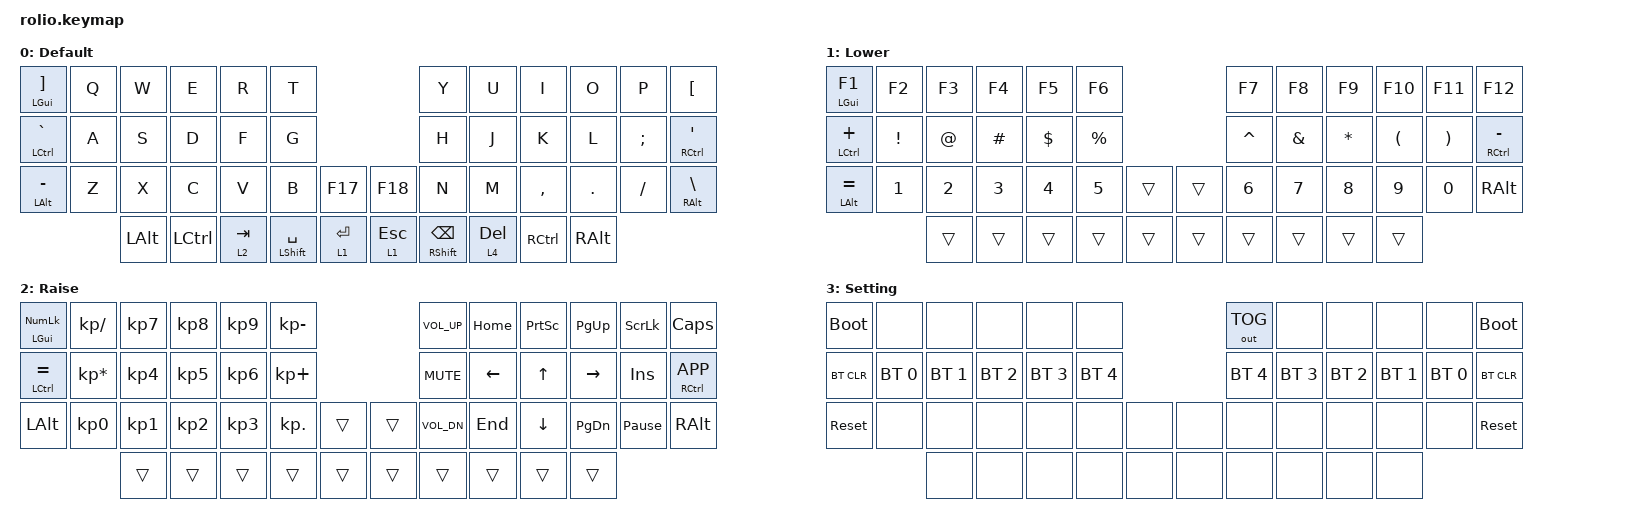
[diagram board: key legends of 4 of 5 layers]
/*
 * Copyright (c) 2023 The ZMK Contributors
 *
 * SPDX-License-Identifier: MIT
 */

#include <behaviors.dtsi>
#include <dt-bindings/zmk/keys.h>
#include <dt-bindings/zmk/bt.h>
#include <dt-bindings/zmk/outputs.h>
#include <dt-bindings/zmk/backlight.h>
#include "elpekenin/behaviors.dtsi"

#define ZMK_POINTING_DEFAULT_SCRL_VAL 100
#include <dt-bindings/zmk/pointing.h>

// Helpful macros borrowed from AndrewMSHowe
#define ___ &trans

// Layer numbers for use by the keymap & macros
#define Default 0
#define Lower 1
#define Raise 2
#define Setting 3
#define Navi 4

/ {
    conditional_layers {
        compatible = "zmk,conditional-layers";

        tri-layer {
            if-layers = <1 2>;
            then-layer = <3>;
        };

        tri-layer1 {
            if-layers = <4 1>;
            then-layer = <3>;
        };
    };


    keymap {
        compatible = "zmk,keymap";

        default_layer {
            display-name = "Default";
            sensor-bindings = <&inc_dec_kp UP DOWN &inc_dec_kp LEFT RIGHT>;
            bindings = <
&mt LGUI RBKT		&kp Q		&kp W			&kp E			&kp R			&kp T												&kp Y				&kp U			&kp I			&kp O		&kp P		&kp LBKT
&mt LCTRL GRAVE		&kp A		&kp S			&kp D			&kp F			&kp G												&kp H				&kp J			&kp K			&kp L		&kp SEMI	&mt RCTRL SQT
&mt LALT MINUS		&kp Z		&kp X			&kp C			&kp V			&kp B				&kp F17 		&kp	F18			&kp N				&kp M			&kp COMMA		&kp DOT		&kp FSLH	&mt RALT BSLH
								&kp LALT		&kp LCTRL		&lt 2 TAB		&mt LSHFT SPACE		&lt 1 RET		&lt 1 ESC		&mt RSHFT BSPC		&lt 4 DEL		&kp RCTRL		&kp RALT
            >;
        };

        Lower_layer {
            display-name = "Lower";
            sensor-bindings = <&inc_dec_kp UP DOWN &inc_dec_kp LEFT RIGHT>;
            bindings = <
&mt LGUI F1		&kp F2		&kp F3		&kp F4		&kp F5		&kp F6										&kp F7		&kp F8		&kp F9		&kp F10		&kp F11		&kp F12
&mt LCTRL PLUS	&kp EXCL	&kp AT		&kp HASH	&kp DLLR	&kp PRCNT									&kp CARET	&kp AMPS	&kp STAR	&kp LPAR	&kp RPAR	&mt RCTRL MINUS
&mt LALT EQUAL	&kp N1		&kp N2		&kp N3		&kp N4		&kp N5		&trans				&trans		&kp N6		&kp N7		&kp N8		&kp N9		&kp N0		&kp RALT
							&trans		&trans		&trans		&trans		&trans				&trans		&trans		&trans		&trans		&trans
            >;
        };

        raise_layer {
            display-name = "Raise";
            sensor-bindings = <&inc_dec_kp UP DOWN &inc_dec_kp LEFT RIGHT>;
            bindings = <
&mt LGUI KP_NUM		&kp KP_SLASH		&kp KP_N7	&kp KP_N8	&kp KP_N9	&kp KP_MINUS							&kp C_VOL_UP	&kp HOME	&kp PSCRN	&kp PG_UP	&kp SLCK			&kp CLCK
&mt LCTRL EQUAL		&kp KP_MULTIPLY		&kp KP_N4	&kp KP_N5	&kp KP_N6	&kp KP_PLUS								&kp C_MUTE		&kp LEFT	&kp UP		&kp RIGHT	&kp INS				&mt RCTRL K_APP
&kp LALT			&kp KP_N0			&kp KP_N1	&kp KP_N2	&kp KP_N3	&kp KP_DOT		&trans		&trans		&kp C_VOL_DN	&kp END		&kp DOWN	&kp PG_DN	&kp PAUSE_BREAK		&kp RALT
										&trans		&trans		&trans		&trans			&trans		&trans		&trans			&trans		&trans		&trans
            >;
        };

        Setting_layer {
            display-name = "Setting";
            sensor-bindings = <&inc_dec_kp UP DOWN &inc_dec_kp LEFT RIGHT>;
            bindings = <
&bootloader		&none			&none			&none			&none			&none										&out OUT_TOG	&none			&none			&none			&none			&bootloader
&bt BT_CLR		&bt BT_SEL 0	&bt BT_SEL 1	&bt BT_SEL 2	&bt BT_SEL 3	&bt BT_SEL 4								&bt BT_SEL 4	&bt BT_SEL 3	&bt BT_SEL 2	&bt BT_SEL 1 	&bt BT_SEL 0	&bt BT_CLR
&sys_reset		&none			&none			&none			&none			&none			&none			&none		&none			&none			&none			&none			&none			&sys_reset
								&none			&none			&none			&none			&none			&none		&none			&none			&none			&none
            >;
        };

        Navi_layer {
            display-name = "Navi";
            sensor-bindings = <&inc_dec_kp UP DOWN &inc_dec_kp LEFT RIGHT>;
            bindings = <
&trans		&trans		&mkp RCLK		&mmv MOVE_UP		&mkp LCLK			&trans								&kp UP			&kp LS(LC(LEFT_ARROW))		&kp LS(LC(RIGHT))		&kp HOME		&trans		&trans
&trans		&trans		&mmv MOVE_LEFT	&mmv MOVE_DOWN		&mmv MOVE_RIGHT		&trans								&kp DOWN		&kp LC(LEFT)				&kp LC(RIGHT)			&kp END			&trans		&trans
&trans		&trans		&trans			&trans				&trans				&trans		&trans		&trans		&kp LG(LS(LEFT))							&kp LS(LG(RIGHT))		&trans			&trans		&trans
						&trans			&trans				&trans				&trans		&trans		&trans		&trans			&trans						&trans					&trans
            >;
      };
};
};

